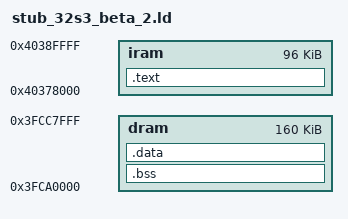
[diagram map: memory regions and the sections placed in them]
/*
 * SPDX-FileCopyrightText: 2019-2022 Espressif Systems (Shanghai) CO LTD
 *
 * SPDX-License-Identifier: GPL-2.0-or-later
 */

MEMORY {
  iram : org = 0x40378000, len = 0x18000
  dram : org = 0x3FCA0000, len = 0x28000
}

ENTRY(stub_main)

SECTIONS {
  .text : ALIGN(4) {
    *(.literal)
    *(.text .text.*)
  } > iram

  .bss : ALIGN(4) {
    _bss_start = ABSOLUTE(.);
    *(.bss)
    _bss_end = ABSOLUTE(.);
  } > dram

  .data : ALIGN(4) {
    *(.data)
    *(.rodata .rodata.*)
  } > dram
}

INCLUDE "rom_32s3_beta_2.ld"
